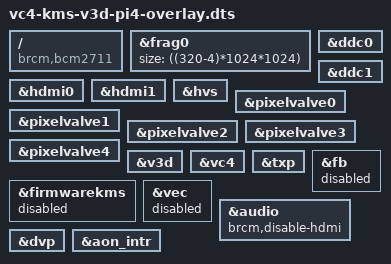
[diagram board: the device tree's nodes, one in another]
/*
 * vc4-kms-v3d-pi4-overlay.dts
 */

/dts-v1/;
/plugin/;

#include <dt-bindings/clock/bcm2835.h>

#include "cma-overlay.dts"

&frag0 {
	size = <((320-4)*1024*1024)>;
};

/ {
	compatible = "brcm,bcm2711";

	fragment@1 {
		target = <&ddc0>;
		__overlay__  {
			status = "okay";
		};
	};

	fragment@2 {
		target = <&ddc1>;
		__overlay__  {
			status = "okay";
		};
	};

	fragment@3 {
		target = <&hdmi0>;
		__overlay__  {
			status = "okay";
		};
	};

	fragment@4 {
		target = <&hdmi1>;
		__overlay__  {
			status = "okay";
		};
	};

	fragment@5 {
		target = <&hvs>;
		__overlay__  {
			status = "okay";
		};
	};

	fragment@6 {
		target = <&pixelvalve0>;
		__overlay__  {
			status = "okay";
		};
	};

	fragment@7 {
		target = <&pixelvalve1>;
		__overlay__  {
			status = "okay";
		};
	};

	fragment@8 {
		target = <&pixelvalve2>;
		__overlay__  {
			status = "okay";
		};
	};

	fragment@9 {
		target = <&pixelvalve3>;
		__overlay__  {
			status = "okay";
		};
	};

	fragment@10 {
		target = <&pixelvalve4>;
		__overlay__  {
			status = "okay";
		};
	};

	fragment@11 {
		target = <&v3d>;
		__overlay__  {
			status = "okay";
		};
	};

	fragment@12 {
		target = <&vc4>;
		__overlay__  {
			status = "okay";
		};
	};

	fragment@13 {
		target = <&txp>;
		__overlay__  {
			status = "okay";
		};
	};

	fragment@14 {
		target = <&fb>;
		__overlay__  {
			status = "disabled";
		};
	};

	fragment@15 {
		target = <&firmwarekms>;
		__overlay__  {
			status = "disabled";
		};
	};

	fragment@16 {
		target = <&vec>;
		__overlay__  {
			status = "disabled";
		};
	};

	fragment@17 {
		target = <&hdmi0>;
		__dormant__  {
			dmas;
		};
	};

	fragment@18 {
		target = <&hdmi1>;
		__dormant__  {
			dmas;
		};
	};

	fragment@19 {
		target = <&audio>;
		__overlay__  {
		    brcm,disable-hdmi;
		};
	};

	fragment@20 {
		target = <&dvp>;
		__overlay__  {
			status = "okay";
		};
	};

	fragment@21 {
		target = <&pixelvalve3>;
		__dormant__  {
			status = "okay";
		};
	};

	fragment@22 {
		target = <&vec>;
		__dormant__  {
			status = "okay";
		};
	};

	fragment@23 {
		target = <&aon_intr>;
		__overlay__  {
			status = "okay";
		};
	};

	__overrides__ {
		audio   = <0>,"!17";
		audio1   = <0>,"!18";
		noaudio = <0>,"=17", <0>,"=18", <0>,"!19";
		composite = <0>, "!1",
			    <0>, "!2",
			    <0>, "!3",
			    <0>, "!4",
			    <0>, "!6",
			    <0>, "!7",
			    <0>, "!8",
			    <0>, "!9",
			    <0>, "!10",
			    <0>, "!16",
			    <0>, "=21",
			    <0>, "=22";
	};
};
